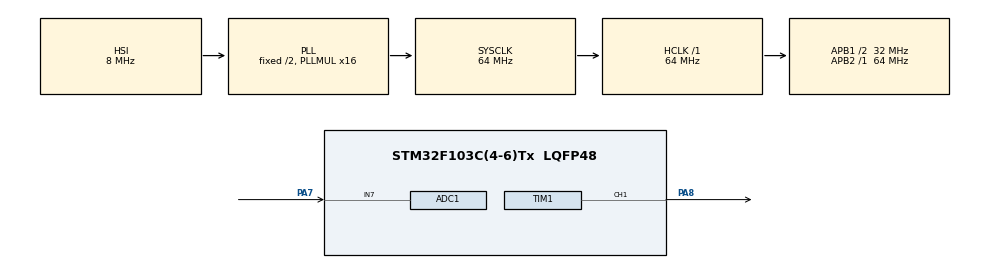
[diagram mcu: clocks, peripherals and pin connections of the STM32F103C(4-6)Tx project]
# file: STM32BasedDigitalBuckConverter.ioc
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ADC1.Channel-0\#ChannelRegularConversion=ADC_CHANNEL_7
ADC1.NbrOfConversionFlag=1
ADC1.Rank-0\#ChannelRegularConversion=1
ADC1.SamplingTime-0\#ChannelRegularConversion=ADC_SAMPLETIME_1CYCLE_5
ADC1.master=1
Mcu.Family=STM32F1
Mcu.Name=STM32F103C(4-6)Tx
Mcu.Package=LQFP48
NVIC.PriorityGroup=NVIC_PRIORITYGROUP_4
PA7.Signal=ADCx_IN7
PA8.Signal=S_TIM1_CH1
ProjectManager.HeapSize=0x200
ProjectManager.StackSize=0x400
ProjectManager.TargetToolchain=STM32CubeIDE
RCC.ADCPresc=RCC_ADCPCLK2_DIV6
RCC.AHBFreq_Value=64000000
RCC.APB1CLKDivider=RCC_HCLK_DIV2
RCC.APB1Freq_Value=32000000
RCC.APB1TimFreq_Value=64000000
RCC.APB2Freq_Value=64000000
RCC.APB2TimFreq_Value=64000000
RCC.HCLKFreq_Value=64000000
RCC.PLLMUL=RCC_PLL_MUL16
RCC.SYSCLKFreq_VALUE=64000000
RCC.SYSCLKSource=RCC_SYSCLKSOURCE_PLLCLK
RCC.USBFreq_Value=64000000
SH.ADCx_IN7.0=ADC1_IN7,IN7
SH.S_TIM1_CH1.0=TIM1_CH1,PWM Generation1 CH1
TIM1.Channel-PWM\ Generation1\ CH1=TIM_CHANNEL_1
TIM1.Period=999
TIM1.Prescaler=0
TIM2.Prescaler=64-1
VP_SYS_VS_ND.Mode=No_Debug
VP_TIM2_VS_ClockSourceINT.Mode=Internal
board=custom

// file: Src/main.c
/* USER CODE BEGIN Header */
/* USER CODE END Header */
#include "main.h"

ADC_HandleTypeDef hadc1;

TIM_HandleTypeDef htim1;
TIM_HandleTypeDef htim2;

/* USER CODE BEGIN PV */
float TargetVoltage = 12.0f;
/* USER CODE END PV */

void SystemClock_Config(void);
static void MX_GPIO_Init(void);
static void MX_TIM1_Init(void);
static void MX_ADC1_Init(void);
static void MX_TIM2_Init(void);

/* USER CODE BEGIN 0 */
uint32_t clamp(uint32_t target, uint32_t min, uint32_t max){
    if (target > max){
        return max;
    } else if (target < min){
        return min;
    } else {
        return target;
    }
}
/* USER CODE END 0 */

int main(void)
{
  /* USER CODE BEGIN 1 */
  uint32_t ADCVal;

  float SensedVoltage;
  float DeltaVoltage;
  uint32_t DeltaTime;

  float Integral = 0;
  float Kp = 5.0f;
  float Ki = 0.1f;
  /* USER CODE END 1 */

  /* MCU Configuration--------------------------------------------------------*/

  /* Reset of all peripherals, Initializes the Flash interface and the Systick. */
  HAL_Init();

  /* Configure the system clock */
  SystemClock_Config();

  /* Initialize all configured peripherals */
  MX_GPIO_Init();
  MX_TIM1_Init();
  MX_ADC1_Init();
  MX_TIM2_Init();
  /* USER CODE BEGIN 2 */
  HAL_TIM_Base_Start(&htim2);
  /* USER CODE END 2 */

  /* Infinite loop */
  /* USER CODE BEGIN WHILE */
  TIM1->CCR1 = 999;
  HAL_TIM_PWM_Start(&htim1, TIM_CHANNEL_1);

  while (1)
  {
      __HAL_TIM_SET_COUNTER(&htim2, 0);
      HAL_ADC_Start(&hadc1);
      HAL_ADC_PollForConversion(&hadc1, 1);
      DeltaTime = __HAL_TIM_GET_COUNTER(&htim2);

      ADCVal = HAL_ADC_GetValue(&hadc1);
      SensedVoltage = 40 * (float)ADCVal / 4095;

      DeltaVoltage = TargetVoltage - SensedVoltage;
      Integral += DeltaVoltage*DeltaTime;

      TIM1->CCR1= clamp((uint32_t)(999-Kp*DeltaVoltage-Ki*Integral), 0, 999);

    /* USER CODE END WHILE */

  }
}

void SystemClock_Config(void)
{
  RCC_OscInitTypeDef RCC_OscInitStruct = {0};
  RCC_ClkInitTypeDef RCC_ClkInitStruct = {0};
  RCC_PeriphCLKInitTypeDef PeriphClkInit = {0};

  /** Initializes the RCC Oscillators according to the specified parameters
  * in the RCC_OscInitTypeDef structure.
  */
  RCC_OscInitStruct.OscillatorType = RCC_OSCILLATORTYPE_HSI;
  RCC_OscInitStruct.HSIState = RCC_HSI_ON;
  RCC_OscInitStruct.HSICalibrationValue = RCC_HSICALIBRATION_DEFAULT;
  RCC_OscInitStruct.PLL.PLLState = RCC_PLL_ON;
  RCC_OscInitStruct.PLL.PLLSource = RCC_PLLSOURCE_HSI_DIV2;
  RCC_OscInitStruct.PLL.PLLMUL = RCC_PLL_MUL16;
  if (HAL_RCC_OscConfig(&RCC_OscInitStruct) != HAL_OK)
  {
    Error_Handler();
  }
  /** Initializes the CPU, AHB and APB buses clocks
  */
  RCC_ClkInitStruct.ClockType = RCC_CLOCKTYPE_HCLK|RCC_CLOCKTYPE_SYSCLK
                              |RCC_CLOCKTYPE_PCLK1|RCC_CLOCKTYPE_PCLK2;
  RCC_ClkInitStruct.SYSCLKSource = RCC_SYSCLKSOURCE_PLLCLK;
  RCC_ClkInitStruct.AHBCLKDivider = RCC_SYSCLK_DIV1;
  RCC_ClkInitStruct.APB1CLKDivider = RCC_HCLK_DIV2;
  RCC_ClkInitStruct.APB2CLKDivider = RCC_HCLK_DIV1;

  if (HAL_RCC_ClockConfig(&RCC_ClkInitStruct, FLASH_LATENCY_2) != HAL_OK)
  {
    Error_Handler();
  }
  PeriphClkInit.PeriphClockSelection = RCC_PERIPHCLK_ADC;
  PeriphClkInit.AdcClockSelection = RCC_ADCPCLK2_DIV6;
  if (HAL_RCCEx_PeriphCLKConfig(&PeriphClkInit) != HAL_OK)
  {
    Error_Handler();
  }
}

static void MX_ADC1_Init(void)
{

  ADC_ChannelConfTypeDef sConfig = {0};

  /** Common config
  */
  hadc1.Instance = ADC1;
  hadc1.Init.ScanConvMode = ADC_SCAN_DISABLE;
  hadc1.Init.ContinuousConvMode = DISABLE;
  hadc1.Init.DiscontinuousConvMode = DISABLE;
  hadc1.Init.ExternalTrigConv = ADC_SOFTWARE_START;
  hadc1.Init.DataAlign = ADC_DATAALIGN_RIGHT;
  hadc1.Init.NbrOfConversion = 1;
  if (HAL_ADC_Init(&hadc1) != HAL_OK)
  {
    Error_Handler();
  }
  /** Configure Regular Channel
  */
  sConfig.Channel = ADC_CHANNEL_7;
  sConfig.Rank = ADC_REGULAR_RANK_1;
  sConfig.SamplingTime = ADC_SAMPLETIME_1CYCLE_5;
  if (HAL_ADC_ConfigChannel(&hadc1, &sConfig) != HAL_OK)
  {
    Error_Handler();
  }

}

static void MX_TIM1_Init(void)
{

  TIM_MasterConfigTypeDef sMasterConfig = {0};
  TIM_OC_InitTypeDef sConfigOC = {0};
  TIM_BreakDeadTimeConfigTypeDef sBreakDeadTimeConfig = {0};

  htim1.Instance = TIM1;
  htim1.Init.Prescaler = 0;
  htim1.Init.CounterMode = TIM_COUNTERMODE_UP;
  htim1.Init.Period = 999;
  htim1.Init.ClockDivision = TIM_CLOCKDIVISION_DIV1;
  htim1.Init.RepetitionCounter = 0;
  htim1.Init.AutoReloadPreload = TIM_AUTORELOAD_PRELOAD_DISABLE;
  if (HAL_TIM_PWM_Init(&htim1) != HAL_OK)
  {
    Error_Handler();
  }
  sMasterConfig.MasterOutputTrigger = TIM_TRGO_RESET;
  sMasterConfig.MasterSlaveMode = TIM_MASTERSLAVEMODE_DISABLE;
  if (HAL_TIMEx_MasterConfigSynchronization(&htim1, &sMasterConfig) != HAL_OK)
  {
    Error_Handler();
  }
  sConfigOC.OCMode = TIM_OCMODE_PWM1;
  sConfigOC.Pulse = 0;
  sConfigOC.OCPolarity = TIM_OCPOLARITY_HIGH;
  sConfigOC.OCNPolarity = TIM_OCNPOLARITY_HIGH;
  sConfigOC.OCFastMode = TIM_OCFAST_DISABLE;
  sConfigOC.OCIdleState = TIM_OCIDLESTATE_RESET;
  sConfigOC.OCNIdleState = TIM_OCNIDLESTATE_RESET;
  if (HAL_TIM_PWM_ConfigChannel(&htim1, &sConfigOC, TIM_CHANNEL_1) != HAL_OK)
  {
    Error_Handler();
  }
  sBreakDeadTimeConfig.OffStateRunMode = TIM_OSSR_DISABLE;
  sBreakDeadTimeConfig.OffStateIDLEMode = TIM_OSSI_DISABLE;
  sBreakDeadTimeConfig.LockLevel = TIM_LOCKLEVEL_OFF;
  sBreakDeadTimeConfig.DeadTime = 0;
  sBreakDeadTimeConfig.BreakState = TIM_BREAK_DISABLE;
  sBreakDeadTimeConfig.BreakPolarity = TIM_BREAKPOLARITY_HIGH;
  sBreakDeadTimeConfig.AutomaticOutput = TIM_AUTOMATICOUTPUT_DISABLE;
  if (HAL_TIMEx_ConfigBreakDeadTime(&htim1, &sBreakDeadTimeConfig) != HAL_OK)
  {
    Error_Handler();
  }
  HAL_TIM_MspPostInit(&htim1);

}

static void MX_TIM2_Init(void)
{

  TIM_ClockConfigTypeDef sClockSourceConfig = {0};
  TIM_MasterConfigTypeDef sMasterConfig = {0};

  htim2.Instance = TIM2;
  htim2.Init.Prescaler = 64-1;
  htim2.Init.CounterMode = TIM_COUNTERMODE_UP;
  htim2.Init.Period = 65535;
  htim2.Init.ClockDivision = TIM_CLOCKDIVISION_DIV1;
  htim2.Init.AutoReloadPreload = TIM_AUTORELOAD_PRELOAD_DISABLE;
  if (HAL_TIM_Base_Init(&htim2) != HAL_OK)
  {
    Error_Handler();
  }
  sClockSourceConfig.ClockSource = TIM_CLOCKSOURCE_INTERNAL;
  if (HAL_TIM_ConfigClockSource(&htim2, &sClockSourceConfig) != HAL_OK)
  {
    Error_Handler();
  }
  sMasterConfig.MasterOutputTrigger = TIM_TRGO_RESET;
  sMasterConfig.MasterSlaveMode = TIM_MASTERSLAVEMODE_DISABLE;
  if (HAL_TIMEx_MasterConfigSynchronization(&htim2, &sMasterConfig) != HAL_OK)
  {
    Error_Handler();
  }

}

static void MX_GPIO_Init(void)
{

  /* GPIO Ports Clock Enable */
  __HAL_RCC_GPIOA_CLK_ENABLE();

}

void Error_Handler(void)
{
  __disable_irq();
  while (1)
  {
  }
}

/************************ (C) COPYRIGHT STMicroelectronics *****END OF FILE****/
